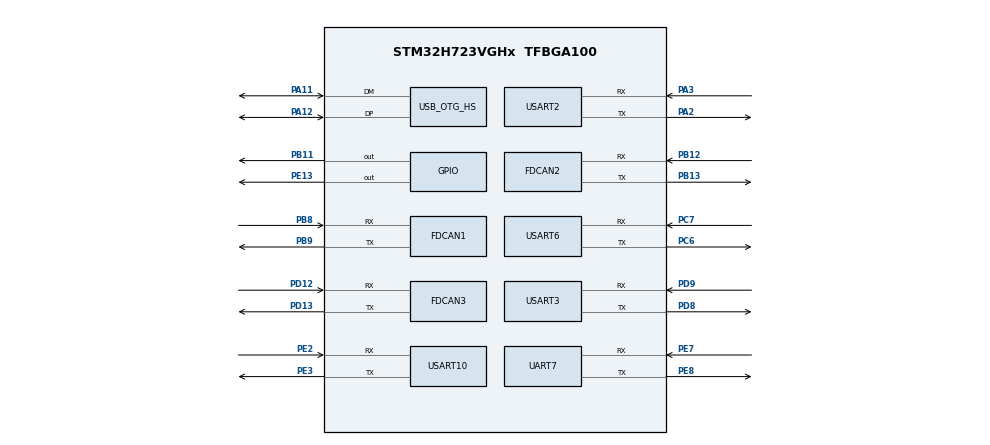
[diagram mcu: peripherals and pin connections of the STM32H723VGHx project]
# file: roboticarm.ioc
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CORTEX_M7.CPU_DCache=Disabled
CORTEX_M7.CPU_ICache=Disabled
CORTEX_M7.default_mode_Activation=1
Dma.Request0=USART10_RX
Dma.Request1=USART10_TX
Dma.USART10_RX.0.Direction=DMA_PERIPH_TO_MEMORY
Dma.USART10_RX.0.EventEnable=DISABLE
Dma.USART10_RX.0.FIFOMode=DMA_FIFOMODE_DISABLE
Dma.USART10_RX.0.Instance=DMA1_Stream0
Dma.USART10_RX.0.MemDataAlignment=DMA_MDATAALIGN_BYTE
Dma.USART10_RX.0.MemInc=DMA_MINC_ENABLE
Dma.USART10_RX.0.Mode=DMA_NORMAL
Dma.USART10_RX.0.PeriphDataAlignment=DMA_PDATAALIGN_BYTE
Dma.USART10_RX.0.PeriphInc=DMA_PINC_DISABLE
Dma.USART10_RX.0.Polarity=HAL_DMAMUX_REQ_GEN_RISING
Dma.USART10_RX.0.Priority=DMA_PRIORITY_LOW
Dma.USART10_RX.0.RequestNumber=1
Dma.USART10_RX.0.SignalID=NONE
Dma.USART10_RX.0.SyncEnable=DISABLE
Dma.USART10_RX.0.SyncPolarity=HAL_DMAMUX_SYNC_NO_EVENT
Dma.USART10_RX.0.SyncRequestNumber=1
Dma.USART10_RX.0.SyncSignalID=NONE
Dma.USART10_TX.1.Direction=DMA_MEMORY_TO_PERIPH
Dma.USART10_TX.1.EventEnable=DISABLE
Dma.USART10_TX.1.FIFOMode=DMA_FIFOMODE_DISABLE
Dma.USART10_TX.1.Instance=DMA1_Stream1
Dma.USART10_TX.1.MemDataAlignment=DMA_MDATAALIGN_BYTE
Dma.USART10_TX.1.MemInc=DMA_MINC_ENABLE
Dma.USART10_TX.1.Mode=DMA_NORMAL
Dma.USART10_TX.1.PeriphDataAlignment=DMA_PDATAALIGN_BYTE
Dma.USART10_TX.1.PeriphInc=DMA_PINC_DISABLE
Dma.USART10_TX.1.Polarity=HAL_DMAMUX_REQ_GEN_RISING
Dma.USART10_TX.1.Priority=DMA_PRIORITY_LOW
Dma.USART10_TX.1.RequestNumber=1
Dma.USART10_TX.1.SignalID=NONE
Dma.USART10_TX.1.SyncEnable=DISABLE
Dma.USART10_TX.1.SyncPolarity=HAL_DMAMUX_SYNC_NO_EVENT
Dma.USART10_TX.1.SyncRequestNumber=1
Dma.USART10_TX.1.SyncSignalID=NONE
FDCAN1.AutoRetransmission=ENABLE
FDCAN1.CalculateBaudRateNominal=1000000
FDCAN1.CalculateTimeBitNominal=1000
FDCAN1.CalculateTimeQuantumNominal=50.0
FDCAN1.DataTimeSeg1=15
FDCAN1.DataTimeSeg2=4
FDCAN1.NominalPrescaler=6
FDCAN1.NominalTimeSeg1=15
FDCAN1.NominalTimeSeg2=4
FDCAN1.RxFifo0ElmtsNbr=8
FDCAN1.StdFiltersNbr=1
FDCAN1.TxFifoQueueElmtsNbr=32
FDCAN2.AutoRetransmission=ENABLE
FDCAN2.CalculateBaudRateNominal=1000000
FDCAN2.CalculateTimeBitNominal=1000
FDCAN2.CalculateTimeQuantumNominal=50.0
FDCAN2.DataTimeSeg1=15
FDCAN2.DataTimeSeg2=4
FDCAN2.MessageRAMOffset=0x104
FDCAN2.NominalPrescaler=6
FDCAN2.NominalTimeSeg1=15
FDCAN2.NominalTimeSeg2=4
FDCAN2.RxFifo0ElmtsNbr=8
FDCAN2.StdFiltersNbr=1
FDCAN2.TxFifoQueueElmtsNbr=32
FDCAN3.AutoRetransmission=ENABLE
FDCAN3.CalculateBaudRateNominal=1000000
FDCAN3.CalculateTimeBitNominal=1000
FDCAN3.CalculateTimeQuantumNominal=50.0
FDCAN3.DataSyncJumpWidth=1
FDCAN3.DataTimeSeg1=15
FDCAN3.DataTimeSeg2=4
FDCAN3.MessageRAMOffset=0x514
FDCAN3.NominalPrescaler=6
FDCAN3.NominalTimeSeg1=15
FDCAN3.NominalTimeSeg2=4
FDCAN3.RxFifo0ElmtsNbr=8
FDCAN3.StdFiltersNbr=1
FDCAN3.TxFifoQueueElmtsNbr=32
FREERTOS.Tasks01=LeftArmTask,48,256,LeftArm_Task,As weak,NULL,Dynamic,NULL,NULL;RightArmTask,48,256,RightArm_Task,As weak,NULL,Dynamic,NULL,NULL;BodyTask,48,256,Body_Task,As weak,NULL,Dynamic,NULL,NULL
Mcu.Family=STM32H7
Mcu.Name=STM32H723VGHx
Mcu.Package=TFBGA100
NVIC.DMA1_Stream0_IRQn=true\:5\:0\:false\:false\:true\:true\:false\:true\:true
NVIC.DMA1_Stream1_IRQn=true\:5\:0\:false\:false\:true\:true\:false\:true\:true
NVIC.FDCAN1_IT0_IRQn=true\:5\:0\:false\:false\:true\:true\:true\:true\:true
NVIC.FDCAN2_IT0_IRQn=true\:5\:0\:false\:false\:true\:true\:true\:true\:true
NVIC.FDCAN3_IT0_IRQn=true\:5\:0\:false\:false\:true\:true\:true\:true\:true
NVIC.OTG_HS_EP1_IN_IRQn=true\:5\:0\:false\:false\:true\:true\:true\:true\:true
NVIC.OTG_HS_EP1_OUT_IRQn=true\:5\:0\:false\:false\:true\:true\:true\:true\:true
NVIC.OTG_HS_IRQn=true\:5\:0\:false\:false\:true\:true\:true\:true\:true
NVIC.PriorityGroup=NVIC_PRIORITYGROUP_4
NVIC.USART10_IRQn=true\:5\:0\:false\:false\:true\:true\:true\:true\:true
PA11.Mode=Device_Only_FS
PA11.Signal=USB_OTG_HS_DM
PA12.Mode=Device_Only_FS
PA12.Signal=USB_OTG_HS_DP
PA2.Mode=Asynchronous
PA2.Signal=USART2_TX
PA3.GPIO_ModeDefaultPP=GPIO_MODE_AF_PP
PA3.GPIO_PuPd=GPIO_NOPULL
PA3.GPIO_Speed=GPIO_SPEED_FREQ_LOW
PA3.Mode=Asynchronous
PA3.Signal=USART2_RX
PB11.Signal=GPIO_Output
PB12.Mode=FDCAN_Activate
PB12.Signal=FDCAN2_RX
PB13.Mode=FDCAN_Activate
PB13.Signal=FDCAN2_TX
PB8.Mode=FDCAN_Activate
PB8.Signal=FDCAN1_RX
PB9.Mode=FDCAN_Activate
PB9.Signal=FDCAN1_TX
PC6.Mode=Asynchronous
PC6.Signal=USART6_TX
PC7.Mode=Asynchronous
PC7.Signal=USART6_RX
PD12.Mode=FDCAN_Activate
PD12.Signal=FDCAN3_RX
PD13.Mode=FDCAN_Activate
PD13.Signal=FDCAN3_TX
PD8.Mode=Asynchronous
PD8.Signal=USART3_TX
PD9.Mode=Asynchronous
PD9.Signal=USART3_RX
PE13.Signal=GPIO_Output
PE2.Mode=Asynchronous
PE2.Signal=USART10_RX
PE3.Mode=Asynchronous
PE3.Signal=USART10_TX
PE7.Mode=Asynchronous
PE7.Signal=UART7_RX
PE8.Mode=Asynchronous
PE8.Signal=UART7_TX
ProjectManager.HeapSize=0x2000
ProjectManager.StackSize=0x2000
ProjectManager.TargetToolchain=MDK-ARM V5.32
RCC.ADCFreq_Value=129000000
RCC.APB1Freq_Value=120000000
RCC.APB2Freq_Value=120000000
RCC.APB3Freq_Value=120000000
RCC.APB4Freq_Value=120000000
RCC.CortexFreq_Value=240000000
RCC.D1PPRE=RCC_APB3_DIV2
RCC.D2PPRE1=RCC_APB1_DIV2
RCC.D2PPRE2=RCC_APB2_DIV2
RCC.D3PPRE=RCC_APB4_DIV2
RCC.DIVM1=4
RCC.DIVN1=15
RCC.DIVP1=1
RCC.HCLKFreq_Value=240000000
RCC.HSE_VALUE=24000000
RCC.PLL2FRACN=0
RCC.PLL3FRACN=0
RCC.PLLFRACN=0
RCC.PLLSourceVirtual=RCC_PLLSOURCE_HSI
RCC.SYSCLKFreq_VALUE=240000000
RCC.SYSCLKSource=RCC_SYSCLKSOURCE_PLLCLK
RCC.USBCLockSelection=RCC_USBCLKSOURCE_HSI48
RCC.USBFreq_Value=48000000
USART10.VirtualMode=VM_ASYNC
USART2.VirtualMode-Asynchronous=VM_ASYNC
USART3.VirtualMode-Asynchronous=VM_ASYNC
USART6.VirtualMode=VM_ASYNC
USB_DEVICE.CLASS_NAME_HS=CDC
USB_DEVICE.VirtualMode=Cdc
USB_DEVICE.VirtualModeHS=Cdc_HS
USB_OTG_HS.VirtualMode-Device_Only_FS=Device_Only_FS
VP_FREERTOS_VS_CMSIS_V2.Mode=CMSIS_V2
VP_MEMORYMAP_VS_MEMORYMAP.Mode=CurAppReg
VP_RCC_USB.Mode=USB_HS
VP_USB_DEVICE_VS_USB_DEVICE_CDC_HS.Mode=CDC_HS
board=custom

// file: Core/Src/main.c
/* USER CODE BEGIN Header */
/**
  ******************************************************************************
  * @file           : main.c
  * @brief          : Main program body (GO1电机控制适配版)
  ******************************************************************************
  * @attention
  *
  * Copyright (c) 2026 STMicroelectronics.
  * All rights reserved.
  *
  * This software is licensed under terms that can be found in the LICENSE file
  * in the root directory of this software component.
  * If no LICENSE file comes with this software, it is provided AS-IS.
  *
  ******************************************************************************
  */
/* USER CODE END Header */
#include "main.h"
#include "cmsis_os.h"
#include "dma.h"
#include "fdcan.h"
#include "usart.h"
#include "usb_device.h"
#include "gpio.h"

/* USER CODE BEGIN Includes */
#include <string.h>
#include <stdio.h>
#include <math.h>
#include "app_init.h"
#include "usbd_cdc_if.h"
/* USER CODE END Includes */

void SystemClock_Config(void);
static void MPU_Config(void);
void MX_FREERTOS_Init(void);

int main(void)
{

  /* MPU Configuration--------------------------------------------------------*/
  MPU_Config();

  /* MCU Configuration--------------------------------------------------------*/

  /* Reset of all peripherals, Initializes the Flash interface and the Systick. */
  HAL_Init();

  /* Configure the system clock */
  SystemClock_Config();

  /* Initialize all configured peripherals */
  MX_GPIO_Init();
  MX_DMA_Init();
  MX_FDCAN1_Init();
  MX_FDCAN2_Init();
  MX_FDCAN3_Init();
  MX_UART7_Init();
  MX_USART2_UART_Init();
  MX_USART3_UART_Init();
  MX_USART6_UART_Init();
  MX_USART10_UART_Init();
  /* USER CODE BEGIN 2 */
  MX_USB_DEVICE_Init();
	Init_InitAll();

  /* USER CODE END 2 */

  /* Init scheduler */
  osKernelInitialize();  /* Call init function for freertos objects (in cmsis_os2.c) */
  MX_FREERTOS_Init();

  /* Start scheduler */
  osKernelStart();

  /* We should never get here as control is now taken by the scheduler */

  /* Infinite loop */
    while (1)
    {

    }
}

void SystemClock_Config(void)
{
  RCC_OscInitTypeDef RCC_OscInitStruct = {0};
  RCC_ClkInitTypeDef RCC_ClkInitStruct = {0};
  RCC_CRSInitTypeDef RCC_CRSInitStruct = {0};

  /** Supply configuration update enable
  */
  HAL_PWREx_ConfigSupply(PWR_LDO_SUPPLY);

  /** Configure the main internal regulator output voltage
  */
  __HAL_PWR_VOLTAGESCALING_CONFIG(PWR_REGULATOR_VOLTAGE_SCALE0);

  while(!__HAL_PWR_GET_FLAG(PWR_FLAG_VOSRDY)) {}

  /** Initializes the RCC Oscillators according to the specified parameters
  * in the RCC_OscInitTypeDef structure.
  */
  RCC_OscInitStruct.OscillatorType = RCC_OSCILLATORTYPE_HSI48|RCC_OSCILLATORTYPE_HSI;
  RCC_OscInitStruct.HSIState = RCC_HSI_DIV1;
  RCC_OscInitStruct.HSICalibrationValue = 64;
  RCC_OscInitStruct.HSI48State = RCC_HSI48_ON;
  RCC_OscInitStruct.PLL.PLLState = RCC_PLL_ON;
  RCC_OscInitStruct.PLL.PLLSource = RCC_PLLSOURCE_HSI;
  RCC_OscInitStruct.PLL.PLLM = 4;
  RCC_OscInitStruct.PLL.PLLN = 15;
  RCC_OscInitStruct.PLL.PLLP = 1;
  RCC_OscInitStruct.PLL.PLLQ = 2;
  RCC_OscInitStruct.PLL.PLLR = 2;
  RCC_OscInitStruct.PLL.PLLRGE = RCC_PLL1VCIRANGE_3;
  RCC_OscInitStruct.PLL.PLLVCOSEL = RCC_PLL1VCOWIDE;
  RCC_OscInitStruct.PLL.PLLFRACN = 0;
  if (HAL_RCC_OscConfig(&RCC_OscInitStruct) != HAL_OK)
  {
    Error_Handler();
  }

  /** Initializes the CPU, AHB and APB buses clocks
  */
  RCC_ClkInitStruct.ClockType = RCC_CLOCKTYPE_HCLK|RCC_CLOCKTYPE_SYSCLK
                              |RCC_CLOCKTYPE_PCLK1|RCC_CLOCKTYPE_PCLK2
                              |RCC_CLOCKTYPE_D3PCLK1|RCC_CLOCKTYPE_D1PCLK1;
  RCC_ClkInitStruct.SYSCLKSource = RCC_SYSCLKSOURCE_PLLCLK;
  RCC_ClkInitStruct.SYSCLKDivider = RCC_SYSCLK_DIV1;
  RCC_ClkInitStruct.AHBCLKDivider = RCC_HCLK_DIV1;
  RCC_ClkInitStruct.APB3CLKDivider = RCC_APB3_DIV2;
  RCC_ClkInitStruct.APB1CLKDivider = RCC_APB1_DIV2;
  RCC_ClkInitStruct.APB2CLKDivider = RCC_APB2_DIV2;
  RCC_ClkInitStruct.APB4CLKDivider = RCC_APB4_DIV2;

  if (HAL_RCC_ClockConfig(&RCC_ClkInitStruct, FLASH_LATENCY_3) != HAL_OK)
  {
    Error_Handler();
  }

  /** Enable the SYSCFG APB clock
  */
  __HAL_RCC_CRS_CLK_ENABLE();

  /** Configures CRS
  */
  RCC_CRSInitStruct.Prescaler = RCC_CRS_SYNC_DIV1;
  RCC_CRSInitStruct.Source = RCC_CRS_SYNC_SOURCE_USB2;
  RCC_CRSInitStruct.Polarity = RCC_CRS_SYNC_POLARITY_RISING;
  RCC_CRSInitStruct.ReloadValue = __HAL_RCC_CRS_RELOADVALUE_CALCULATE(48000000,1000);
  RCC_CRSInitStruct.ErrorLimitValue = 34;
  RCC_CRSInitStruct.HSI48CalibrationValue = 32;

  HAL_RCCEx_CRSConfig(&RCC_CRSInitStruct);
}

 /* MPU Configuration */

void MPU_Config(void)
{
  MPU_Region_InitTypeDef MPU_InitStruct = {0};

  /* Disables the MPU */
  HAL_MPU_Disable();

  /** Initializes and configures the Region and the memory to be protected
  */
  MPU_InitStruct.Enable = MPU_REGION_ENABLE;
  MPU_InitStruct.Number = MPU_REGION_NUMBER0;
  MPU_InitStruct.BaseAddress = 0x0;
  MPU_InitStruct.Size = MPU_REGION_SIZE_4GB;
  MPU_InitStruct.SubRegionDisable = 0x87;
  MPU_InitStruct.TypeExtField = MPU_TEX_LEVEL0;
  MPU_InitStruct.AccessPermission = MPU_REGION_NO_ACCESS;
  MPU_InitStruct.DisableExec = MPU_INSTRUCTION_ACCESS_DISABLE;
  MPU_InitStruct.IsShareable = MPU_ACCESS_SHAREABLE;
  MPU_InitStruct.IsCacheable = MPU_ACCESS_NOT_CACHEABLE;
  MPU_InitStruct.IsBufferable = MPU_ACCESS_NOT_BUFFERABLE;

  HAL_MPU_ConfigRegion(&MPU_InitStruct);
  /* Enables the MPU */
  HAL_MPU_Enable(MPU_PRIVILEGED_DEFAULT);

}

void Error_Handler(void)
{
  __disable_irq();
  while (1)
  {
  }
}

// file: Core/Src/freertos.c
/* USER CODE BEGIN Header */
/**
  ******************************************************************************
  * File Name          : freertos.c
  * Description        : Code for freertos applications
  ******************************************************************************
  * @attention
  *
  * Copyright (c) 2026 STMicroelectronics.
  * All rights reserved.
  *
  * This software is licensed under terms that can be found in the LICENSE file
  * in the root directory of this software component.
  * If no LICENSE file comes with this software, it is provided AS-IS.
  *
  ******************************************************************************
  */
/* USER CODE END Header */

#include "FreeRTOS.h"
#include "task.h"
#include "main.h"
#include "cmsis_os.h"

/* Definitions for LeftArmTask */
osThreadId_t LeftArmTaskHandle;
const osThreadAttr_t LeftArmTask_attributes = {
  .name = "LeftArmTask",
  .stack_size = 256 * 4,
  .priority = (osPriority_t) osPriorityRealtime,
};
/* Definitions for RightArmTask */
osThreadId_t RightArmTaskHandle;
const osThreadAttr_t RightArmTask_attributes = {
  .name = "RightArmTask",
  .stack_size = 256 * 4,
  .priority = (osPriority_t) osPriorityRealtime,
};
/* Definitions for BodyTask */
osThreadId_t BodyTaskHandle;
const osThreadAttr_t BodyTask_attributes = {
  .name = "BodyTask",
  .stack_size = 256 * 4,
  .priority = (osPriority_t) osPriorityRealtime,
};

void LeftArm_Task(void *argument);
void RightArm_Task(void *argument);
void Body_Task(void *argument);

extern void MX_USB_DEVICE_Init(void);
void MX_FREERTOS_Init(void); /* (MISRA C 2004 rule 8.1) */

void MX_FREERTOS_Init(void) {

  /* Create the thread(s) */
  /* creation of LeftArmTask */
  LeftArmTaskHandle = osThreadNew(LeftArm_Task, NULL, &LeftArmTask_attributes);

  /* creation of RightArmTask */
  RightArmTaskHandle = osThreadNew(RightArm_Task, NULL, &RightArmTask_attributes);

  /* creation of BodyTask */
  BodyTaskHandle = osThreadNew(Body_Task, NULL, &BodyTask_attributes);

}

__weak void LeftArm_Task(void *argument)
{
  /* init code for USB_DEVICE */
  MX_USB_DEVICE_Init();
  for(;;)
  {
    osDelay(1);
  }
}

__weak void RightArm_Task(void *argument)
{
  for(;;)
  {
    osDelay(1);
  }
}

__weak void Body_Task(void *argument)
{
  for(;;)
  {
    osDelay(1);
  }
}
